# RTS5921 register map
Vendor: Realtek Semiconductor Corp.; Series: RTS5921 Series; File version: 0.01
CPU: ARMV8MBL r0p0, little endian, MPU, no FPU, VTOR, 3 interrupt priority bits
Registers are 32-bit, read-write, reset 0x0 unless marked. A register's access mark holds for its fields unless they carry their own. Offsets are from the block's base; [hi:lo] are bit positions; {n}, {i} and the like mark numbered series.

## WDT — WDT Controller
Base 0x40100980
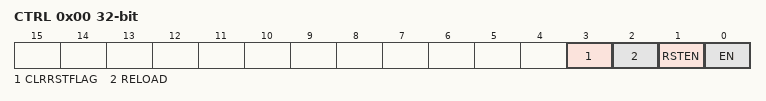
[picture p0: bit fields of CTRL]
0x00 CTRL — CONTROL REGISTER
  [3] CLRRSTFLAG write-1-clears — Clear WDT reset flag
    0=DO_NOTHING; 1=CLR (Clear WDT reset flag)
  [2] RELOAD — Reload WDT Counter
    0=DO_NOTHING; 1=RELOAD (Reload WDT counter)
  [1] RSTEN — Enable WDT to Reset System
    0=DISABLE (Disable WDT to reset system); 1=ENABLE (Enable WDT to reset system)
  [0] EN — Enable WDT
    0=DISABLE (Disable WDT); 1=ENABLE (Enable WDT)
0x04 STS ro — STATUS REGISTER
  [0] RSTFLAG — Reset Flag
    0=NOT_OCCURRED (WDT reset is not occurred); 1=OCCURRED (WDT reset is occurred)
0x08 CNT — INITIAL COUNTER REGISTER
0x0C DIV — DIVIDER REGISTER
0x10 INTEN — INTERRUPT ENABLE REGISTER
  [0] WDTINTEN — Enable WDT Interrupt
    0=DISBLE (Disable WDT interrupt); 1=ENABLE (Enable WDT interrupt)

## I2CDBG — I2C Debug Controller
Base 0x40100A00
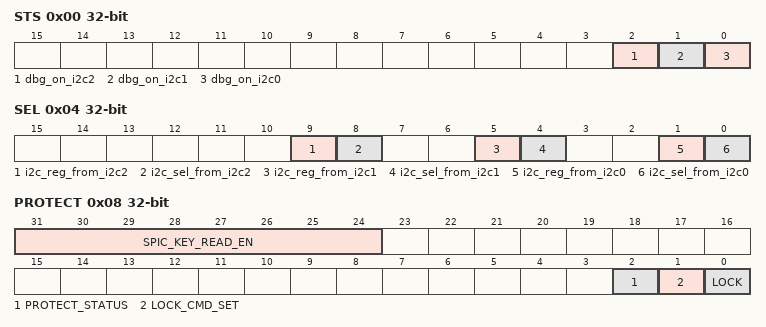
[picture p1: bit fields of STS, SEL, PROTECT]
0x00 STS
  [2] dbg_on_i2c2 ro — nan
  [1] dbg_on_i2c1 ro — nan
  [0] dbg_on_i2c0 ro — nan
0x04 SEL
  [9] i2c_reg_from_i2c2 ro — nan
  [8] i2c_sel_from_i2c2 ro — nan
  [5] i2c_reg_from_i2c1 ro — nan
  [4] i2c_sel_from_i2c1 ro — nan
  [1] i2c_reg_from_i2c0 ro — nan
  [0] i2c_sel_from_i2c0 ro — nan
0x08 PROTECT
  [31:24] SPIC_KEY_READ_EN — nan
  [2] PROTECT_STATUS — nan
  [1] LOCK_CMD_SET — nan
  [0] LOCK — nan
0x0C UNLOCKKEYH
  [31:0] KEY_H — nan
0x10 UNLOCKKEYL
  [31:0] KEY_L — nan
0x14 KEYH
  [31:0] KEY_H — nan
0x18 KEYL
  [31:0] KEY_L — nan

## KBM — Keyboard Matrix Controller
Base 0x40122100
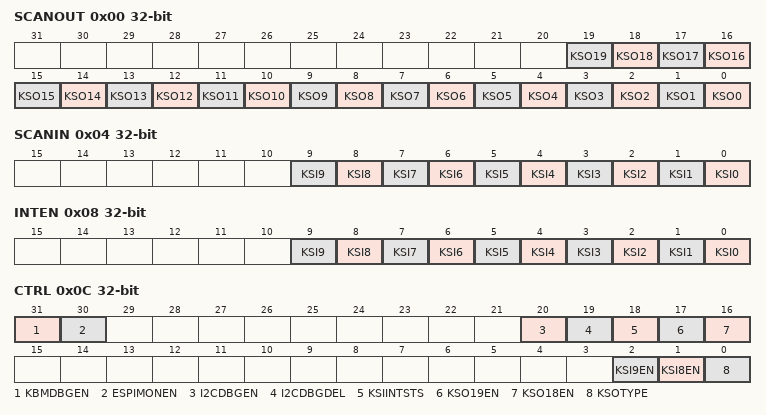
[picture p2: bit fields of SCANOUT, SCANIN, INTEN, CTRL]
0x00 SCANOUT — SCAN OUT CONTROL REGISTER
  [n] KSO{n} (n=0..19) — KSO Output Level
    0=LOW (KSO output low); 1=HIGH (KSO output high)
0x04 SCANIN ro — SACN INPUT STATUS REGISTER
  [n] KSI{n} (n=0..9) — KSI Input Level
    0=LOW (KSI input is low); 1=HIGH (KSI input is high)
0x08 INTEN — INTERRUPT ENABLE REGISTER
  [n] KSI{n} (n=0..9) — KSI Interrupt Enable
    0=DISABLE (KSI interrupt disable); 1=ENABLE (KSI interrupt enable)
0x0C CTRL — CONTROL REGISTER
  [31] KBMDBGEN — KBM Debug Enable
    0=DISABLE (Disable KBM Debug); 1=ENABLE (Enable KBM Debug)
  [30] ESPIMONEN — ESPI Monitor Enable
    0=DISABLE (Disable ESPI Monitor); 1=ENABLE (Enable ESPI Monitor)
  [20] I2CDBGEN — I2C Debug Enable
    0=DISABLE (Disable I2C Debug); 1=ENABLE (Enable I2C Debug)
  [19] I2CDBGDEL — I2C Debug Select
    0=I2CDBG (KBM I2C Debug); 1=I2CDBGREG (I2C Debug Refer Bit20)
  [18] KSIINTSTS — KSI Interrupt Status
    0=NOT_OCCURRED (KSI interrupt is not occurred); 1=OCCURRED (KSI interrupt is occurred)
  [17] KSO19EN — Enable KSO19
    0=DISABLE (Disable KSO19); 1=ENABLE (Enable KSO19)
  [16] KSO18EN — Enable KSO18
    0=DISABLE (Disable KSO18); 1=ENABLE (Enable KSO18)
  [2] KSI9EN — Enable KSI9
    0=DISABLE (Disable KSI9); 1=ENABLE (Enable KSI9)
  [1] KSI8EN — Enable KSI8
    0=DISABLE (Disable KSI8); 1=ENABLE (Enable KSI8)
  [0] KSOTYPE — Output Type of KSO pin
    0=PUSH_PULL; 1=OPEN_DRAIN
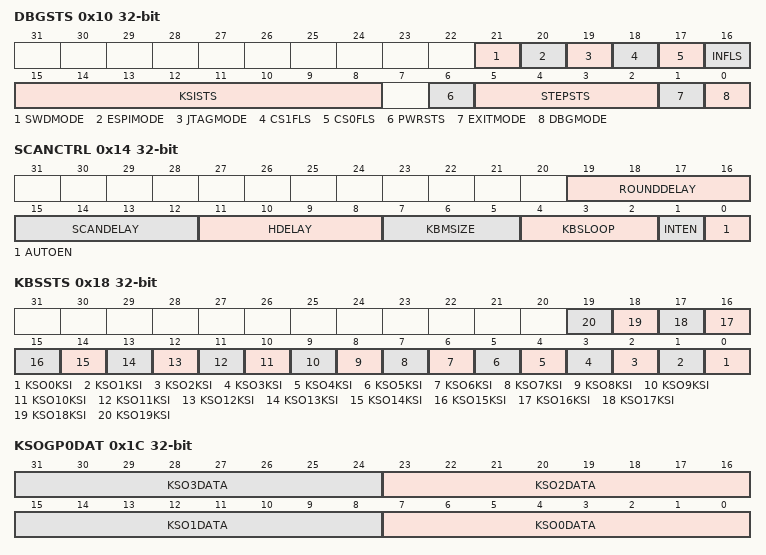
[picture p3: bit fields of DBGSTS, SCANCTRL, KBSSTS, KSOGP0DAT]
0x10 DBGSTS ro — DWBUG STATUS REGISTER
  [21] SWDMODE — SWD Mode Select
    0=NONE (Not in SWD Mode); 1=SELECTED (SWD Mode)
  [20] ESPIMODE — eSPI Mode Select
    0=NONE (Not in eSPI Mode); 1=SELECTED (eSPI Mode)
  [19] JTAGMODE — Jtag Mode Select
    0=NONE (Not in Jtag Mode); 1=SELECTED (Jtag Mode)
  [18] CS1FLS — CS1 Flash Select
    0=NONE (Not in CS1 Flash Mode); 1=SELECTED (CS1 Flash Mode)
  [17] CS0FLS — CS0 Flash Select
    0=NONE (Not in CS0 Flash Mode); 1=SELECTED (CS0 Flash Mode)
  [16] INFLS — Internal Flash Select
    0=NONE (Not in Internal Flash Mode); 1=SELECTED (Internal Flash Mode)
  [15:8] KSISTS — KSIs Status
  [6] PWRSTS — KBM Power Status
    0=NOPWR (KBM without Power); 1=POWER (KBM Powered)
  [5:2] STEPSTS — Entry Debug Status
  [1] EXITMODE — Exit Debug Mode Status
    0=NORMAL (Normal Operation); 1=EXIT (Exit Debug Mode)
  [0] DBGMODE — Debug Mode Status
    0=NORMAL (Normal Operation); 1=DEBUG (In Debug Mode)
0x14 SCANCTRL — KB SCAN CONTROL REGISTER
  [19:16] ROUNDDELAY — SCAN ROUND DELAY
  [15:12] SCANDELAY — KSI SCAN DELAY
    0=11US; 1=13US; 2=15US; 3=17US; 4=19US; 5=21US; 6=23US; 7=25US; 8=27US; 9=29US
  [11:8] HDELAY — KSO HIGH DELAY
    0=23US; 1=31US; 2=39US; 3=47US; 4=55US; 5=64US; 6=71US; 7=79US; 8=87US; 9=95US
  [7:5] KBMSIZE — KBS MATRIX SIZE
    {v}=8X{v+16} ({v+16} KSOs) (v=0..4)
  [4:2] KBSLOOP — KBS AUTO SCAN LOOP
    {v}={v+1} Round (v=0..7)
  [1] INTEN — KBS AUTO SCAN INTERRUPT ENABLE
    0=LOW (Disable KBS Interrupt); 1=HIGH (Eable KBS Interrupt)
  [0] AUTOEN — KBS AUTO SCAN ENABLE
    0=LOW (Disable KBS); 1=HIGH (Eable KBS)
0x18 KBSSTS — KBSCAN STATUS REGISTER
  [n] KSO{n}KSI (n=0..19) — KSO Sampling SKI status
0x1C KSOGP0DAT ro — KSO GROUP0 DATA REGISTER
  [8n+7:8n] KSO{n}DATA (n=0..3)
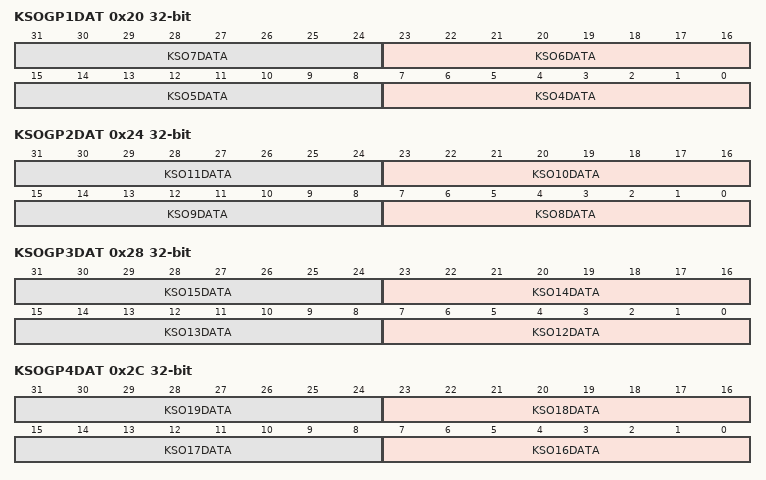
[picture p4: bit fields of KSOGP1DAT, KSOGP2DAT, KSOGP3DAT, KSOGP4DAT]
0x20 KSOGP1DAT ro — KSO GROUP1 DATA REGISTER
  [8n-25:8n-32] KSO{n}DATA (n=4..7)
0x24 KSOGP2DAT ro — KSO GROUP2 DATA REGISTER
  [8n-57:8n-64] KSO{n}DATA (n=8..11)
0x28 KSOGP3DAT ro — KSO GROUP3 DATA REGISTER
  [8n-89:8n-96] KSO{n}DATA (n=12..15)
0x2C KSOGP4DAT ro — KSO GROUP4 DATA REGISTER
  [8n-121:8n-128] KSO{n}DATA (n=16..19)
